# MKE18F16 register map
Vendor: Freescale Semiconductor, Inc.; Series: Kinetis_E; File version: 1.6
CPU: CM4 r0p1, little endian, no MPU, FPU, VTOR, 4 interrupt priority bits
Registers are 32-bit, read-write, reset 0x0 unless marked. A register's access mark holds for its fields unless they carry their own. Offsets are from the block's base; [hi:lo] are bit positions; {n}, {i} and the like mark numbered series.

## ADC0 — Analog-to-Digital Converter
Base 0x4003B000; register names take the prefix ADC0_
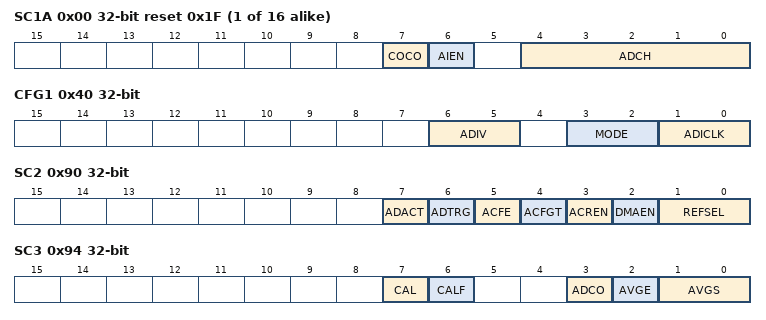
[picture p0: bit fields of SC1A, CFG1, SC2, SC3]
0x00 SC1{x} (x=A,B,C,D,E,F,G,H,I,J,K,L,M,N,O,P; step 0x4) reset 0x1F — ADC Status and Control Registers 1
  [7] COCO ro — Conversion Complete Flag
    0=Conversion is not completed; 1=Conversion is completed
  [6] AIEN — Interrupt Enable
    0=Conversion complete interrupt is disabled; 1=Conversion complete interrupt is enabled
  [4:0] ADCH — Input channel select
    {v}=AD{v} is selected as input (v=0..15); 18=AD18 is selected as input; 19=AD19 is selected as input; 21=AD21 is selected as input; 22=AD22 is selected as input; 23=AD23 is selected as input; 24=ATX Force; 25=ATX Sense; 26=Temp Sensor; 27=Band Gap; 28=AD28 is selected as input; 29=VREFSH is selected as input. Voltage reference selected is determined by SC2[REFSEL].; 30=VREFSL is selected as input. Voltage reference selected is determined by SC2[REFSEL].; 31=Module is disabled
0x40 CFG1 — ADC Configuration Register 1
  [6:5] ADIV — Clock Divide Select
    0=The divide ratio is 1 and the clock rate is input clock; 1=The divide ratio is 2 and the clock rate is (input clock)/2; 2=The divide ratio is 4 and the clock rate is (input clock)/4; 3=The divide ratio is 8 and the clock rate is (input clock)/8
  [3:2] MODE — Conversion mode selection
    0=8-bit conversion; 1=12-bit conversion; 2=10-bit conversion
  [1:0] ADICLK — Input Clock Select
    {v}=Alternate clock {v+1} (ADC_ALTCLK{v+1}) (v=0..3)
0x44 CFG2 reset 0xC — ADC Configuration Register 2
  [7:0] SMPLTS — Sample Time Select
0x48 R{x} (x=A,B,C,D,E,F,G,H,I,J,K,L,M,N,O,P; step 0x4) ro — ADC Data Result Register
  [11:0] D — Data result
{0x84+4i} CV{i} (i=1..2) — Compare Value Registers
  [11:0] CV — Compare Value.
0x90 SC2 — Status and Control Register 2
  [7] ADACT ro — Conversion Active
    0=Conversion not in progress; 1=Conversion in progress
  [6] ADTRG — Conversion Trigger Select
    0=Software trigger selected; 1=Hardware trigger selected
  [5] ACFE — Compare Function Enable
    0=Compare function disabled; 1=Compare function enabled
  [4] ACFGT — Compare Function Greater Than Enable
    0=Configures less than threshold, outside range not inclusive and inside range not inclusive; functionality based on the values placed in CV1 and CV2; 1=Configures greater than or equal to threshold, outside and inside ranges inclusive; functionality based on the values placed in CV1 and CV2
  [3] ACREN — Compare Function Range Enable
    0=Range function disabled. Only CV1 is compared.; 1=Range function enabled. Both CV1 and CV2 are compared.
  [2] DMAEN — DMA Enable
    0=DMA is disabled; 1=DMA is enabled and will assert the ADC DMA request during an ADC conversion complete event noted when any of the SC1n[COCO] flags is asserted
  [1:0] REFSEL — Voltage Reference Selection
    0=Default voltage reference pin pair, that is, external pins VREFH and VREFL; 1=Alternate reference pair, that is, VALTH and VALTL . This pair may be additional external pins or internal sources depending on the MCU configuration. See the chip configuration information for details specific to this MCU
0x94 SC3 — Status and Control Register 3
  [7] CAL — Calibration
  [6] CALF — Calibration Failed Flag
    0=Calibration completed normally; 1=Calibration failed. ADC accuracy specifications are not guaranteed.
  [3] ADCO — Continuous Conversion Enable
    0=One conversion or one set of conversions if the hardware average function is enabled, that is, AVGE=1, after initiating a conversion; 1=Continuous conversions or sets of conversions if the hardware average function is enabled, that is, AVGE=1, after initiating a conversion
  [2] AVGE — Hardware Average Enable
    0=Hardware average function disabled; 1=Hardware average function enabled
  [1:0] AVGS — Hardware Average Select
    0=4 samples averaged; 1=8 samples averaged; 2=16 samples averaged; 3=32 samples averaged
0x98 BASE_OFS reset 0x43 — ADC Offset Correction Register
  [7:0] BA_OFS — Base Offset Error Correction Value
0x9C OFS — ADC Offset Correction Register
  [11:0] OFS — Offset Error Correction Value
0xA0 USR_OFS — ADC USER Offset Correction Register
  [7:0] USR_OFS — USER Offset Error Correction Value
0xA4 XOFS reset 0x6 — ADC X Offset Correction Register
  [5:0] OFS — Offset Error Correction Value
0xA8 YOFS reset 0x37 — ADC Y Offset Correction Register
  [7:0] YOFS — Y Offset Error Correction Value
0xAC G reset 0x2F0 — ADC Gain Register
  [10:0] G — Gain
0xB0 UG reset 0x4 — ADC User Gain Register
  [9:0] UG — User Gain
0xB4 CLPS reset 0x2E — ADC General Calibration Value Register
  [6:0] CLPS — Calibration Value
0xB8 CLP3 reset 0x180 — ADC Plus-Side General Calibration Value Register
  [9:0] CLP3 — Calibration Value
0xBC CLP2 reset 0xB8 — ADC Plus-Side General Calibration Value Register
  [8:0] CLP2 — Calibration Value
0xC0 CLP1 reset 0x5C — ADC Plus-Side General Calibration Value Register
  [8:0] CLP1 — Calibration Value
0xC4 CLP0 reset 0x2E — ADC Plus-Side General Calibration Value Register
  [7:0] CLP0 — Calibration Value
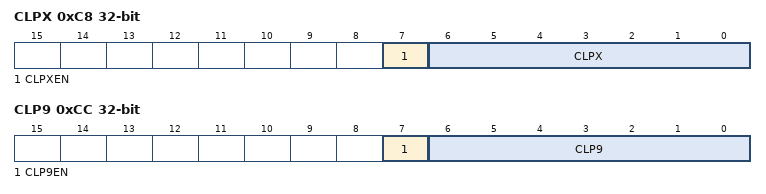
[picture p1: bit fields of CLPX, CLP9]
0xC8 CLPX — ADC Plus-Side General Calibration Value Register
  [7] CLPXEN — CLPX compare bit
  [6:0] CLPX — Calibration Value
0xCC CLP9 — ADC Plus-Side General Calibration Value Register
  [7] CLP9EN — CLP9 compare bit
  [6:0] CLP9 — Calibration Value
0xD0 CLPS_OFS — ADC General Calibration Value Register
  [3:0] CLPS_OFS — CLPS Offset
0xD4 CLP3_OFS — ADC Plus-Side General Calibration Value Register
  [3:0] CLP3_OFS — CLP3 Offset
0xD8 CLP2_OFS — ADC Plus-Side General Calibration Value Register
  [3:0] CLP2_OFS — CLP2 Offset
0xDC CLP1_OFS — ADC Plus-Side General Calibration Value Register
  [3:0] CLP1_OFS — CLP1 Offset
0xE0 CLP0_OFS — ADC Plus-Side General Calibration Value Register
  [3:0] CLP0_OFS — CLP0 Offset
0xE4 CLPX_OFS reset 0x443 — ADC Plus-Side General Calibration Value Register
  [11:0] CLPX_OFS — CLPX Offset
0xE8 CLP9_OFS reset 0x243 — ADC Plus-Side General Calibration Value Register
  [11:0] CLP9_OFS — CLP9 Offset

## ADC1 — Analog-to-Digital Converter
Base 0x40027000; register names take the prefix ADC1_
Registers as ADC0.

## ADC2 — Analog-to-Digital Converter
Base 0x4003C000; register names take the prefix ADC2_
Registers as ADC0.
